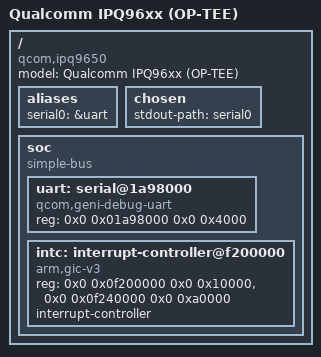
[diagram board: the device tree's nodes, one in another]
// SPDX-License-Identifier: BSD-3-Clause
/*
 * Copyright (c) Qualcomm Technologies, Inc. and/or its subsidiaries.
 *
 * Secure world view of IPQ96xx as seen by OP-TEE.
 *
 * Only the properties OP-TEE consumes are described, so properties such as
 * clocks, interrupts and pinctrl are left out. The compile-time values in
 * plat-qcom stay the fallback for every node.
 */

/dts-v1/;

/ {
	compatible = "qcom,ipq9650";
	model = "Qualcomm IPQ96xx (OP-TEE)";
	#address-cells = <2>;
	#size-cells = <2>;

	aliases {
		serial0 = &uart;
	};

	chosen {
		stdout-path = "serial0";
	};

	soc {
		compatible = "simple-bus";
		#address-cells = <2>;
		#size-cells = <2>;
		ranges;

		uart: serial@1a98000 {
			compatible = "qcom,geni-debug-uart";
			reg = <0x0 0x01a98000 0x0 0x4000>;
		};

		intc: interrupt-controller@f200000 {
			compatible = "arm,gic-v3";
			reg = <0x0 0x0f200000 0x0 0x10000>,	/* GICD */
			      <0x0 0x0f240000 0x0 0xa0000>;	/* GICR */
			interrupt-controller;
			/* OP-TEE resolves at most 3 interrupt cells */
			#interrupt-cells = <3>;
		};
	};
};
